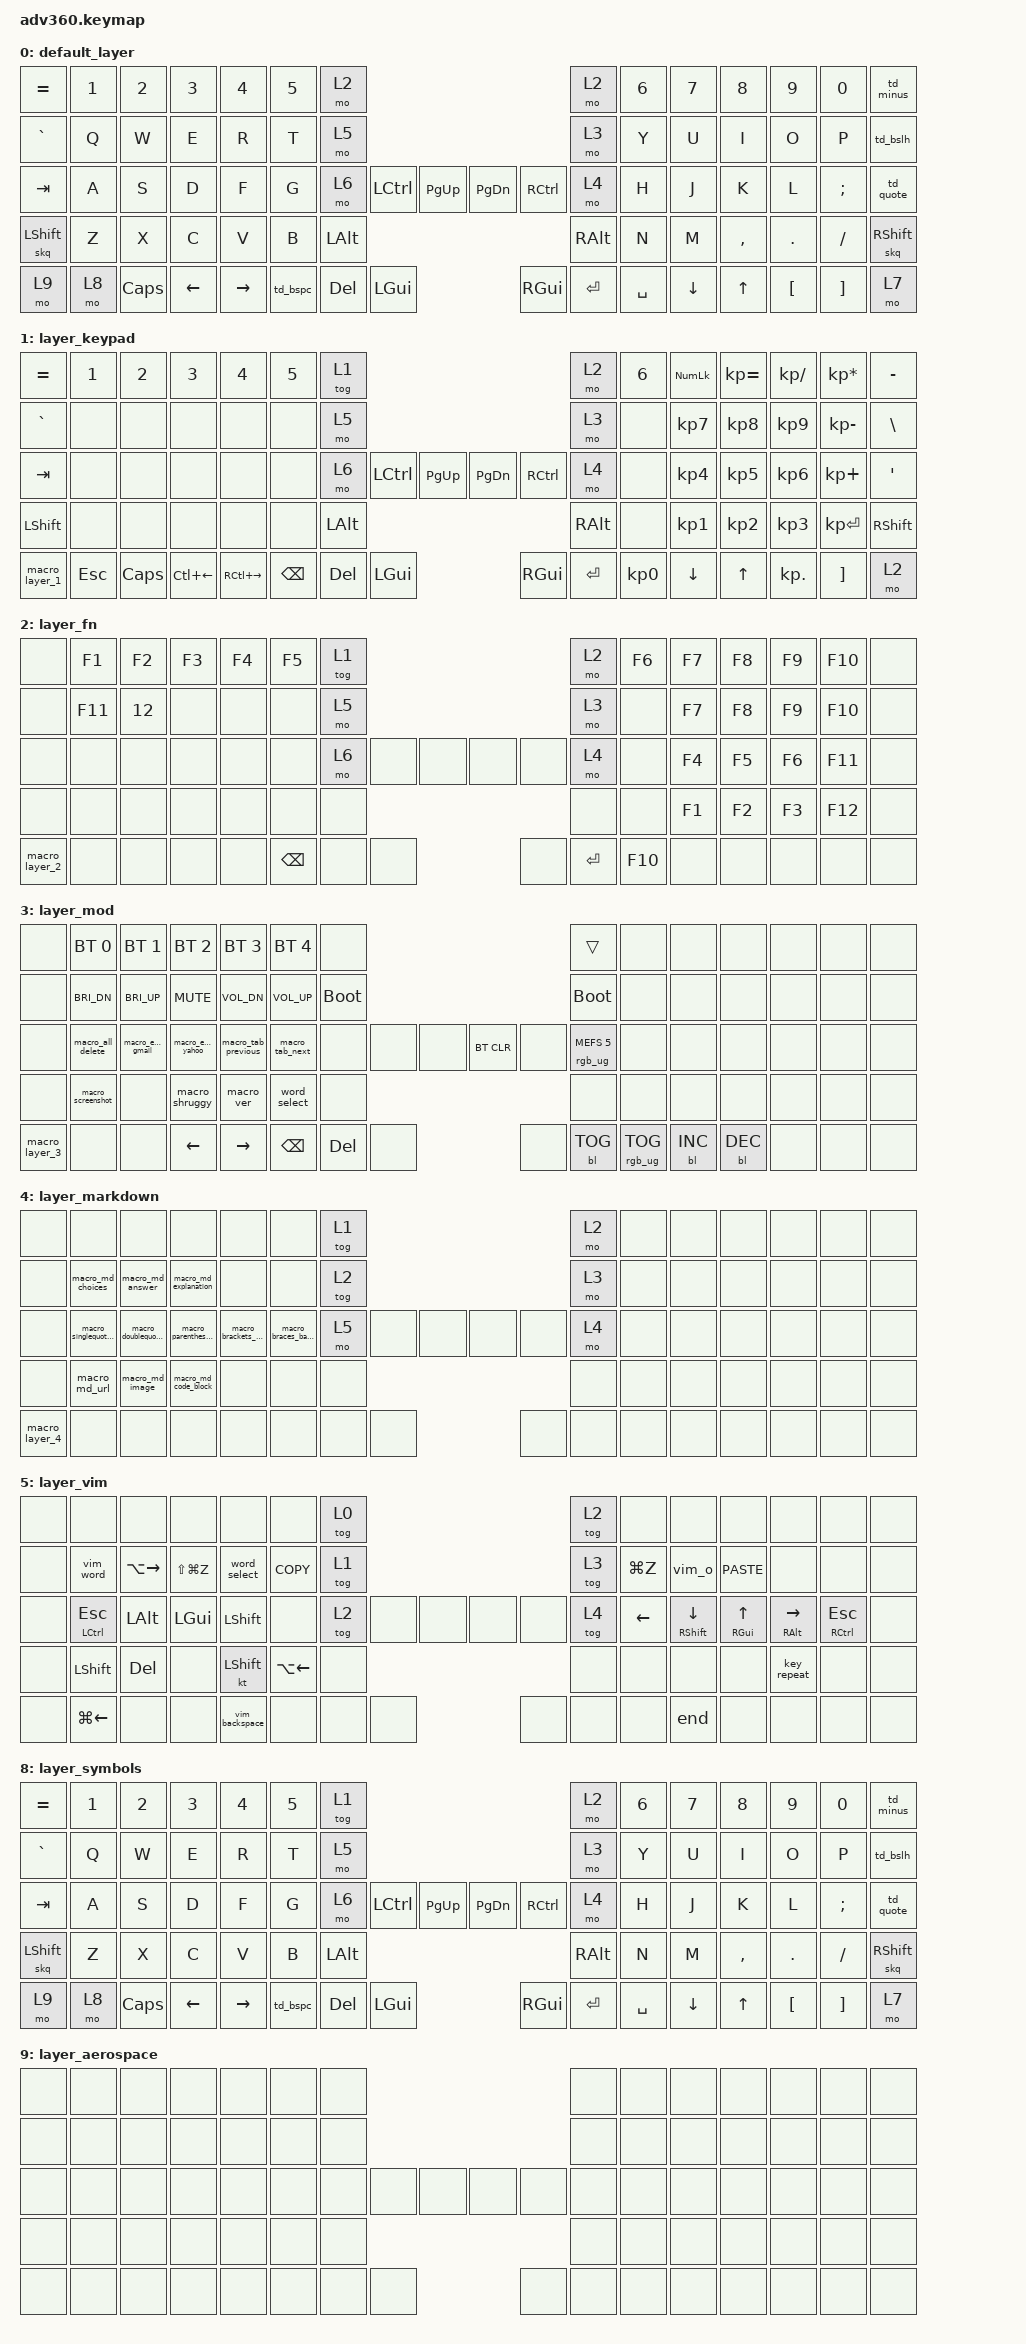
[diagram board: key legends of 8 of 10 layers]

/*
 * Copyright (c) 2020 The ZMK Contributors
 *
 * SPDX-License-Identifier: MIT
 */


/* THIS FILE WAS GENERATED!
 *
 * This file was generated automatically. You may or may not want to
 * edit it directly.
 */

#include <behaviors.dtsi>
#include <dt-bindings/zmk/keys.h>
#include <dt-bindings/zmk/bt.h>
#include <dt-bindings/zmk/rgb.h>
#include <dt-bindings/zmk/backlight.h>
#include <dt-bindings/zmk/mouse.h>
#include "combos.dtsi"

&sl {
    release-after-ms = <2000>;
};



/ {

  behaviors {
    #include "macros.dtsi"
    #include "version.dtsi"
    #include "macro_layers.dtsi"
    #include "macro_urls.dtsi"
    #include "macro_markdown.dtsi"

    hm: homerow_mods {
        compatible = "zmk,behavior-hold-tap";
        label = "HOMEROW_MODS";
        #binding-cells = <2>;
        tapping-term-ms = <200>;
        quick_tap_ms = <175>;
        flavor = "tap-preferred";
        bindings = <&kp>, <&kp>;
    };
  };

    keymap {
        compatible = "zmk,keymap";

/* layer 0 -> base, letters */
/* layer 1 -> keypad */
/* layer 2 -> function - combo: ESC, LARROW */
/* layer 3 -> mod, various functions */
/* layer 4 -> markdown */
/* layer 5 -> vim */
/* layer 6 -> mouse */
/* layer 7 -> macros */
/* layer 8 -> symbols */
/* layer 9 -> aerospace */

default_layer {
  bindings = <
       &kp EQUAL    &kp N1     &kp N2     &kp N3         &kp N4    &kp N5       &mo 2                                                  &mo 2       &kp N6      &kp N7          &kp N8        &kp N9    &kp N0      &td_minus
       &kp GRAVE     &kp Q      &kp W      &kp E          &kp R     &kp T       &mo 5                                                  &mo 3       &kp Y       &kp U           &kp I         &kp O     &kp P       &td_bslh 
         &kp TAB     &kp A      &kp S      &kp D          &kp F     &kp G       &mo 6  &kp LCTRL  &kp PG_UP     &kp PG_DN  &kp RCTRL   &mo 4       &kp H       &kp J           &kp K         &kp L     &kp SEMI    &td_quote
      &skq LSHFT     &kp Z      &kp X      &kp C          &kp V     &kp B                          &kp LALT     &kp RALT                           &kp N       &kp M           &kp COMMA     &kp DOT   &kp FSLH    &skq RSHFT
           &mo 9     &mo 8   &kp CAPS   &kp LEFT      &kp RIGHT              &td_bspc    &kp DEL   &kp LGUI     &kp RGUI   &kp ENTER   &kp SPACE               &kp DOWN_ARROW  &kp UP_ARROW  &kp LBKT  &kp RBKT    &mo 7
  >;
};


/* layer 1 -> keypad */
layer_keypad {
  bindings = <
      &kp EQUAL   &kp N1    &kp N2        &kp N3         &kp N4  &kp N5      &tog 1                                                     &mo 2  &kp N6  &kp KP_NUM  &kp KP_EQUAL  &kp KP_DIVIDE  &kp KP_MULTIPLY  &kp MINUS
      &kp GRAVE    &none     &none         &none          &none   &none      &mo 5                                                     &mo 3   &none   &kp KP_N7     &kp KP_N8      &kp KP_N9     &kp KP_MINUS   &kp BSLH
        &kp TAB    &none     &none         &none          &none   &none      &mo 6  &kp LCTRL  &kp PG_UP     &kp PG_DN  &kp RCTRL      &mo 4   &none   &kp KP_N4     &kp KP_N5      &kp KP_N6      &kp KP_PLUS    &kp SQT
      &kp LSHFT    &none     &none         &none          &none   &none                         &kp LALT      &kp RALT                         &none   &kp KP_N1     &kp KP_N2      &kp KP_N3     &kp KP_ENTER  &kp RSHFT
 &macro_layer_1  &kp ESC  &kp CAPS  &kp LC(LEFT)  &kp RC(RIGHT)           &kp BSPC    &kp DEL   &kp LGUI      &kp RGUI  &kp ENTER  &kp KP_N0            &kp DOWN  &kp UP_ARROW     &kp KP_DOT         &kp RBKT      &mo 2
  >;
};


/* layer 2 -> function - combo: ESC, LARROW */
layer_fn {
  bindings = <
          &none    &kp F1  &kp F2  &kp F3  &kp F4  &kp F5     &tog 1                                                &mo 2    &kp F6  &kp F7  &kp F8   &kp F9    &kp F10   &none
          &none   &kp F11  &kp 12   &none   &none    &none     &mo 5                                                &mo 3    &none   &kp F7  &kp F8   &kp F9    &kp F10   &none
          &none     &none   &none   &none   &none    &none     &mo 6  &none  &none                  &none  &none    &mo 4    &none   &kp F4  &kp F5   &kp F6    &kp F11   &none
          &none     &none   &none   &none   &none    &none                   &none                  &none                    &none   &kp F1  &kp F2   &kp F3    &kp F12   &none
 &macro_layer_2     &none   &none   &none   &none           &kp BSPC  &none  &none                  &none  &kp RET  &kp F10          &none   &none    &none     &none     &none
  >;
};


/* layer 3 -> mod, various functions */
layer_mod {
  bindings = <
          &none       &bt BT_SEL 0         &bt BT_SEL 1         &bt BT_SEL 2         &bt BT_SEL 3         &bt BT_SEL 4            &none                                                 &trans                   &none    &none       &none        &none   &none   &none
          &none       &kp C_BRI_DN         &kp C_BRI_UP           &kp C_MUTE         &kp C_VOL_DN         &kp C_VOL_UP      &bootloader                                                 &bootloader              &none    &none       &none        &none   &none   &none
          &none  &macro_all_delete   &macro_email_gmail   &macro_email_yahoo  &macro_tab_previous      &macro_tab_next            &none       &none   &none     &bt BT_CLR   &none      &rgb_ug RGB_MEFS_CMD 5   &none    &none       &none        &none   &none   &none
          &none  &macro_screenshot                &none       &macro_shruggy           &macro_ver         &word_select                                &none     &none                                            &none    &none       &none        &none   &none   &none
 &macro_layer_3              &none                &none             &kp LEFT            &kp RIGHT                              &kp BSPC  &kp DELETE   &none     &none        &bl BL_TOG  &rgb_ug RGB_TOG                  &bl BL_INC  &bl BL_DEC   &none   &none   &none
  >;
};


/* layer 4 -> markdown */
layer_markdown {
  bindings = <
          &none                     &none                     &none                    &none                 &none               &none   &tog 1                                               &mo 2   &none  &none  &none  &none  &none  &none
          &none         &macro_md_choices          &macro_md_answer    &macro_md_explanation                 &none               &none   &tog 2                                               &mo 3   &none  &none  &none  &none  &none  &none
          &none  &macro_singlequotes_back  &macro_doublequotes_back  &macro_parentheses_back  &macro_brackets_back  &macro_braces_back    &mo 5  &none  &none                  &none  &none   &mo 4   &none  &none  &none  &none  &none  &none
          &none             &macro_md_url           &macro_md_image     &macro_md_code_block                 &none               &none                  &none                  &none                  &none  &none  &none  &none  &none  &none
 &macro_layer_4                     &none                     &none                    &none                 &none                        &none  &none  &none                  &none  &none   &none          &none  &none  &none  &none  &none
  >;
};


/* layer 5 -> vim */
layer_vim {
  bindings = <
            &none                   &none           &none          &none           &none         &none    &tog 0                                                &tog 2      &none         &none                 &none                   &none                &none             &none
            &none                &vim_word  &kp LA(RIGHT)  &kp LS(LG(Z))    &word_select    &kp K_COPY    &tog 1                                                &tog 3      &kp LG(Z)     &vim_o                &kp K_PASTE             &none                &none             &none
            &none  &hm LEFT_CONTROL ESCAPE       &kp LALT   &kp LEFT_GUI  &kp LEFT_SHIFT         &none    &tog 2   &none      &none       &none     &none       &tog 4      &kp LEFT      &hm RIGHT_SHIFT DOWN  &hm RIGHT_GUI UP_ARROW  &hm RIGHT_ALT RIGHT  &hm RCTRL ESCAPE  &none
            &none           &kp LEFT_SHIFT     &kp DELETE          &none  &kt LEFT_SHIFT  &kp LA(LEFT)                        &none       &none                             &none         &none                 &none                   &key_repeat          &none             &none
            &none             &kp LG(LEFT)          &none          &none  &vim_backspace                   &none   &none      &none       &none     &none       &none                     &end                  &none                   &none                &none             &none
            >;
        };


/* layer 6 -> mouse */

       layer_mouse {
            bindings = <
            &none  &none &none &none &none  &none   &trans                                    &trans    &none             &none                   &none             &none             &none      &none
            &none  &none &none &none &none  &none   &trans                                    &trans    &none             &none                   &none             &none             &none      &none
            &none  &none &none &none &none  &none   &trans   &trans  &trans   &trans  &trans  &trans    &none             &mkp LCLK               &kp LA(DOWN_ARROW)   &kp LA(UP_ARROW)     &mkp RCLK  &none
            &none  &none &none &none &none  &none                    &trans   &trans                    &none             &none                   &none             &none             &none      &none
            &none  &none &none &none &none  &none   &trans   &trans  &trans   &trans  &trans  &trans    &kp LA(UP_ARROW)  &kp LA(DOWN_ARROW)      &none             &none             &none      &none
            >;
        };

/* layer 7 -> macros */

       layer_macros {
            bindings = <
            &none  &none           &none          &none          &none           &none              &trans             &mo 2    &none   &none   &none   &none   &none      &none
            &none  &macro_espn     &macro_youtube &macro_ww      &macro_heb      &none              &trans             &mo 3    &none   &none   &none   &none   &none      &none
            &none  &macro_copilot  &macro_gemini  &macro_claude  &macro_chatgpt  &macro_perplexity  &trans   &trans    &mo 4    &none   &none   &none   &none   &none      &none
            &none  &none           &none          &none          &none           &none                       &trans    &trans           &none   &none   &none   &none      &none
            &none  &none           &none          &none          &none           &none              &trans   &trans    &trans   &trans  &trans  &trans  &none   &none      &none
            >;
        };

/* layer 8 -> symbols */

       layer_symbols {
            bindings = <
       &kp EQUAL    &kp N1     &kp N2     &kp N3         &kp N4    &kp N5       &tog 1                                                 &mo 2       &kp N6      &kp N7          &kp N8        &kp N9    &kp N0      &td_minus
       &kp GRAVE     &kp Q      &kp W      &kp E          &kp R     &kp T       &mo 5                                                  &mo 3       &kp Y       &kp U           &kp I         &kp O     &kp P       &td_bslh 
         &kp TAB     &kp A      &kp S      &kp D          &kp F     &kp G       &mo 6  &kp LCTRL  &kp PG_UP     &kp PG_DN  &kp RCTRL   &mo 4       &kp H       &kp J           &kp K         &kp L     &kp SEMI    &td_quote
      &skq LSHFT     &kp Z      &kp X      &kp C          &kp V     &kp B                          &kp LALT     &kp RALT                           &kp N       &kp M           &kp COMMA     &kp DOT   &kp FSLH    &skq RSHFT
           &mo 9     &mo 8   &kp CAPS   &kp LEFT      &kp RIGHT              &td_bspc    &kp DEL   &kp LGUI     &kp RGUI   &kp ENTER   &kp SPACE               &kp DOWN_ARROW  &kp UP_ARROW  &kp LBKT  &kp RBKT    &mo 7
            >;
        };

/* layer 9 -> aerospace */
       layer_aerospace {
            bindings = <
                &none &none &none &none &none &none &none                            &none &none &none &none &none &none &none
                &none &none &none &none &none &none &none                            &none &none &none &none &none &none &none
                &none &none &none &none &none &none &none &none &none    &none &none &none &none &none &none &none &none &none
                &none &none &none &none &none &none             &none    &none             &none &none &none &none &none &none
                &none &none &none &none &none       &none &none &none    &none &none &none       &none &none &none &none &none
            >;
        };
    };



};

